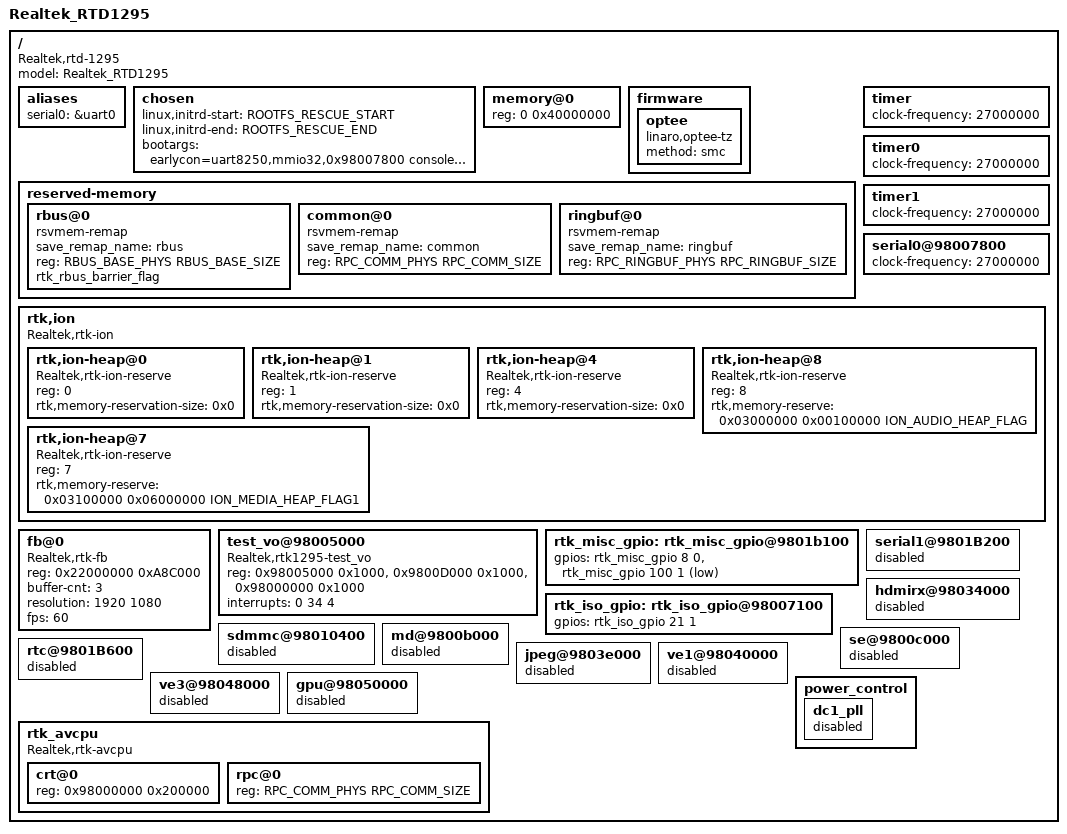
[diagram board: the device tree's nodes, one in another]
/dts-v1/;
#include <dt-bindings/soc/rtd129x,memory.h>

/* 0x00000000 ~ 0x0002ffff */
/memreserve/ SYS_BOOTCODE_MEMBASE SYS_BOOTCODE_MEMSIZE;
/* 0x0001f000 ~ 0x0001ffff */
/memreserve/ RPC_COMM_PHYS RPC_COMM_SIZE;
/* 0x01ffe000 ~ 0x02001fff */
/memreserve/ RPC_RINGBUF_PHYS RPC_RINGBUF_SIZE;
/* 0x02200000 ~ 0x02dfffff */
/memreserve/ ROOTFS_RESCUE_START ROOTFS_RESCUE_SIZE;
/memreserve/ 0x03000000 0x00100000;
/memreserve/ 0x03100000 0x06000000;
/* 0x10000000 ~ 0x10013fff */
/memreserve/ ACPU_IDMEM_PHYS ACPU_IDMEM_SIZE;
/* 0x1fc00000 ~ 0x1fc00fff */
/memreserve/ ACPU_BOOTCODE_PHYS ACPU_BOOTCODE_SIZE;
/* Framebuffer */
/memreserve/ 0x22000000 0x17BB000;

#include "rtd-1295.dtsi"

/ {
	model= "Realtek_RTD1295";
	compatible = "Realtek,rtd-1295";

	aliases {
		serial0 = &uart0;
	};

	chosen {
		linux,initrd-start = <ROOTFS_RESCUE_START>;
		linux,initrd-end = <ROOTFS_RESCUE_END>;
		bootargs ="earlycon=uart8250,mmio32,0x98007800 console=ttyS0,115200 cma=64m@576m init=/init androidboot.hardware=kylin androidboot.storage=emmc loglevel=4";
	};

	memory@0 {
		device_type = "memory";
		reg = <0 0x40000000>; /* 1024 MB */
	};

	firmware {
		optee {
			compatible = "linaro,optee-tz";
			method = "smc";
		};
	};

	reserved-memory {
		#address-cells = <1>;
		#size-cells = <1>;
		ranges;

		rbus@0 {
			compatible = "rsvmem-remap";
			save_remap_name = "rbus";
			reg = <RBUS_BASE_PHYS RBUS_BASE_SIZE>;
			rtk_rbus_barrier_flag;
		};

		common@0 {
			compatible = "rsvmem-remap";
			save_remap_name = "common";
			reg = <RPC_COMM_PHYS RPC_COMM_SIZE>;
		};

		ringbuf@0 {
			compatible = "rsvmem-remap";
			save_remap_name = "ringbuf";
			reg = <RPC_RINGBUF_PHYS RPC_RINGBUF_SIZE>;
		};
	};

	timer {
		clock-frequency = <27000000>;
	};

	timer0 {
		clock-frequency = <27000000>;
	};

	timer1 {
		clock-frequency = <27000000>;
	};

	serial0@98007800 {
		clock-frequency = <27000000>;
	};

	rtk,ion {
		compatible = "Realtek,rtk-ion";
		#address-cells = <1>;
		#size-cells = <0>;

		rtk,ion-heap@0 { /* SYSTEM_HEAP */
			compatible = "Realtek,rtk-ion-reserve";
			reg = <0>;
			rtk,memory-reservation-size = <0x0>;
		};

		rtk,ion-heap@1 { /* System contig */
			compatible = "Realtek,rtk-ion-reserve";
			reg = <1>;
			rtk,memory-reservation-size = <0x0>;
		};

		rtk,ion-heap@4 { /* DMA_HEAP */
			compatible = "Realtek,rtk-ion-reserve";
			reg = <4>;
			rtk,memory-reservation-size = <0x0>;
		};

		rtk,ion-heap@8 { /* Audio */
			compatible = "Realtek,rtk-ion-reserve";
			reg = <8>;
			rtk,memory-reserve = <
				0x03000000
				0x00100000
				ION_AUDIO_HEAP_FLAG>;
		};

		rtk,ion-heap@7 { /* TYPE_MEDIA */
			compatible = "Realtek,rtk-ion-reserve";
			reg = <7>;
			rtk,memory-reserve = <
				0x03100000
				0x06000000
				ION_MEDIA_HEAP_FLAG1>;
		};
	};

	fb@0 {
		compatible = "Realtek,rtk-fb";
		reg = <0x22000000 0xA8C000>;
		buffer-cnt = <3>;
		resolution = <1920 1080>;
		fps = <60>;
	};

	test_vo@98005000 {
		compatible = "Realtek,rtk1295-test_vo";
		reg = <0x98005000 0x1000>,
			<0x9800D000 0x1000>,
			<0x98000000 0x1000>;
		//interrupts = <0 31 4>;
		interrupts = <0 34 4>;
	};

	rtk_misc_gpio: rtk_misc_gpio@9801b100 {
		gpios = <&rtk_misc_gpio 8 0 0>, /* install button, input, default N/A */
			<&rtk_misc_gpio 100 1 1>; /* audio dac unmute , output, default high */
	};

	rtk_iso_gpio: rtk_iso_gpio@98007100 {
		gpios = <&rtk_iso_gpio 21 1 0>; /* igpio21, output, default low */
	};

	serial1@9801B200 {
		status = "disabled";
	};

	hdmirx@98034000 {
		status = "disabled";
	};

	sdmmc@98010400 {
		status = "disabled";
	};

	md@9800b000 {
		status = "disabled";
	};

	se@9800c000 {
		status = "disabled";
	};

	rtc@9801B600 {
		status = "disabled";
	};

	jpeg@9803e000 {
		status = "disabled";
	};

	ve1@98040000 {
		status = "disabled";
	};

	ve3@98048000 {
		status = "disabled";
	};

	gpu@98050000 {
		status = "disabled";
	};

	power_control {
		dc1_pll {
			status = "disabled";
		} ;
	};

	rtk_avcpu {
		compatible = "Realtek,rtk-avcpu";
		#address-cells = <1>;
		#size-cells = <1>;
		ranges;

		crt@0 {
			reg = <0x98000000 0x200000>;
		};

		rpc@0 {
			reg = <RPC_COMM_PHYS RPC_COMM_SIZE>;
		};
	};
};

